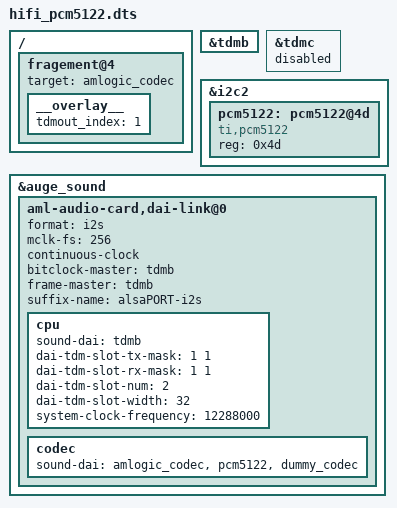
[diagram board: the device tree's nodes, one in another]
/dts-v1/;
/plugin/;

/ {
	fragment@0 {
		target = <&tdmb>;

		__overlay__ {
			status = "okay";
		};
	};

	fragment@1 {
		target = <&tdmc>;

		__overlay__ {
			status = "disabled";
		};
	};

	fragment@2 {
		target = <&i2c2>;

		__overlay__ {
			status = "okay";

			pcm5122: pcm5122@4d {
				compatible = "ti,pcm5122";
				reg = <0x4d>;
				#sound-dai-cells = <0>;
				status = "okay";
			};
		};
	};

	fragment@3 {
		target = <&auge_sound>;

		__overlay__ {
			status = "okay";

			aml-audio-card,dai-link@0 {
				format = "i2s";
				mclk-fs = <256>;
				continuous-clock;
				bitclock-master = <&tdmb>;
				frame-master = <&tdmb>;
				suffix-name = "alsaPORT-i2s";
				cpu {
					sound-dai = <&tdmb>;
					dai-tdm-slot-tx-mask = <1 1>;
					dai-tdm-slot-rx-mask = <1 1>;
					dai-tdm-slot-num = <2>;
					dai-tdm-slot-width = <32>;
					system-clock-frequency = <12288000>;
				};
				codec {
					/* remove amlogic_codec if lineout disable */
					sound-dai = <&amlogic_codec &pcm5122 &dummy_codec>;
				};
			};
		};
	};

	/* remove this if lineout disable */
	fragement@4 {
		target = <&amlogic_codec>;

		__overlay__ {
			tdmout_index = <1>;
		};
	};
};
